# STM32U385 register map
File version: 1.0
CPU: CM33 r0p1, little endian, MPU, FPU, 4 interrupt priority bits
Registers are 32-bit, read-write, reset 0x0 unless marked. A register's access mark holds for its fields unless they carry their own. Offsets are from the block's base; [hi:lo] are bit positions; {n}, {i} and the like mark numbered series.

## GTZC1_MPCBB1 — GTZC1_MPCBB1 Address block
Base 0x40032C00
Same registers: SEC_GTZC1_MPCBB1 0x50032C00
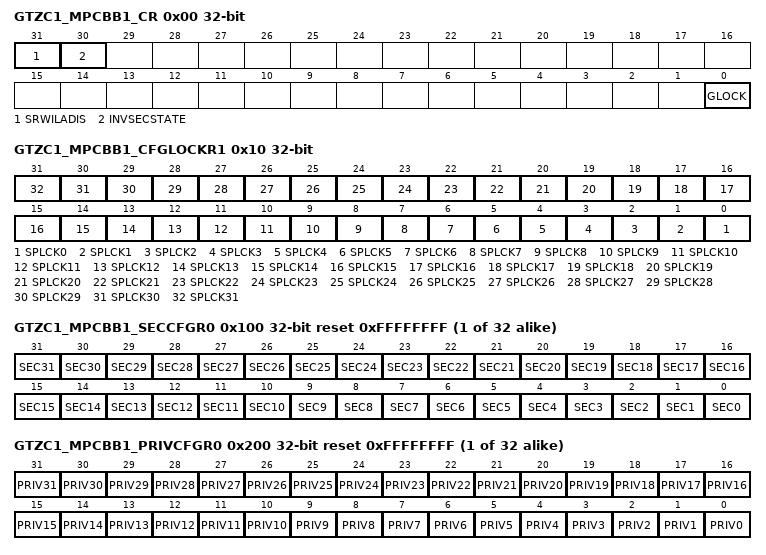
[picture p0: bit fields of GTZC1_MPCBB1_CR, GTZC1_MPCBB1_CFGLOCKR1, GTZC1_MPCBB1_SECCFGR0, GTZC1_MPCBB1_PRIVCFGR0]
0x00 GTZC1_MPCBB1_CR — GTZC1 SRAM1 MPCBB control register
  [31] SRWILADIS — This bit disables the detection of an illegal access when a secure read/write transaction access a non-secure blocks of the block-based SRAM (secure fetch on non-secure block is always considered illegal). 0: enabled, secure read/write access not allowed on non-secure SRAM block 1: disabled, secure read/write access allowed on non-secure SRAM block
    0=enabled, secure read/write access not allowed on non-secure SRAM block; 1=disabled, secure read/write access allowed on non-secure SRAM block
  [30] INVSECSTATE — This bit is used to define the internal SRAMs clocks control in RCC as secure or not. 0: SRAMs clocks are secure if a secure area exists in the MPCBB. It is non secure if there is no secure area. 1: SRAMs clocks are non-secure even if a secure area exists in the MPCBB, and secure even if no secure block is set in the MPCBB.
    0=SRAMs clocks are secure if a secure area exists in the MPCBB. It is non secure if there is no secure area.; 1=SRAMs clocks are non-secure even if a secure area exists in the MPCBB, and secure even if no secure block is set in the MPCBB
  [0] GLOCK — This bit is cleared by default and once set, it can not be reset until system reset. 0: control register not locked 1: control register locked
    0=control register not locked; 1=control register locked
0x10 GTZC1_MPCBB1_CFGLOCKR1 — GTZC1 SRAM1 MPCBB configuration lock register 1
  [n] SPLCK{n} (n=0..31) — This bit is set by software and can be cleared only by system reset. 0: GTZC1_MPCBB1_SECCFGR{n} and GTZC1_MPCBB1_PRIVCFGR{n} can be written. 1: Writes to GTZC1_MPCBB1_SECCFGR{n} and GTZC1_MPCBB1_PRIVCFGR{n} are ignored
    0=GTZC1_MPCBB1_SECCFGR{n} and GTZC1_MPCBB1_PRIVCFGR{n} can be written; 1=Writes to GTZC1_MPCBB1_SECCFGR{n} and GTZC1_MPCBB1_PRIVCFGR{n} are ignored
{0x100+4i} GTZC1_MPCBB1_SECCFGR{i} reset 0xFFFFFFFF (i=0..31) — GTZC1 SRAM1 MPCBB security configuration for super-block {i} register
  [n] SEC{n} (n=0..31) — Unprivileged write to this bit is ignored if PRIV{n} bit is set in GTZC1_MPCBB1_PRIVCFGR{i}. Writes are ignored if SPLCK{i} bit is set in GTZC1_MPCBB1_CFGLOCKR1. 0: Non-secure access only to block {n}, belonging to super-block {i}. Secure access is also allowed if the SRWILADIS bit is set in GTZC1_MPCBBz_CR. 1: Secure access only to block {n}, belonging to super-block {i}.
    0=Non-secure access only to block {n}, belonging to super-block {i}. Secure access is also allowed if the SRWILADIS bit is set in GTZC1_MPCBBz_CR.; 1=Secure access only to block {n}, belonging to super-block {i}
{0x200+4i} GTZC1_MPCBB1_PRIVCFGR{i} reset 0xFFFFFFFF (i=0..31) — GTZC1 SRAM1 MPCBB privileged configuration for super-block {i} register
  [n] PRIV{n} (n=0..31) — Non-secure write to this bit is ignored if SEC{n} bit is set in GTZC1_MPCBB1_SECCFGR{i}. Writes are ignored if SPLCK{i} bit is set in GTZC1_MPCBB1_CFGLOCKR1. 0: Privileged and unprivileged access to block {n}, belonging to super-block {i} 1: Only privileged access to block {n}, belonging to super-block {i}
    0=Privileged and unprivileged access to block {n}, belonging to super-block {i}; 1=Only privileged access to block {n}, belonging to super-block {i}

## GTZC1_MPCBB2 — GTZC1_MPCBB2 Address block
Base 0x40033000
Same registers: SEC_GTZC1_MPCBB2 0x50033000
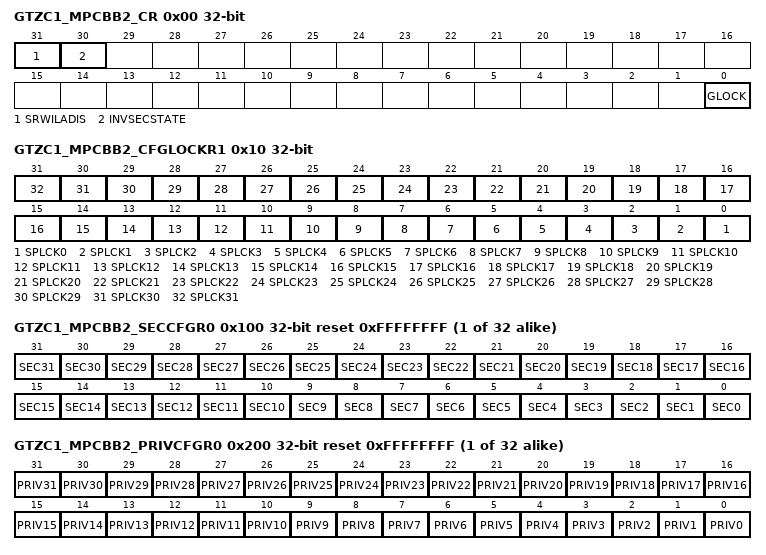
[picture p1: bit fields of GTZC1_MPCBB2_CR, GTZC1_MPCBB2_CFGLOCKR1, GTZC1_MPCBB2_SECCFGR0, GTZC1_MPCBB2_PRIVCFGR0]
0x00 GTZC1_MPCBB2_CR — GTZC1 SRAM2 MPCBB control register
  [31] SRWILADIS — This bit disables the detection of an illegal access when a secure read/write transaction access a non-secure blocks of the block-based SRAM (secure fetch on non-secure block is always considered illegal). 0: enabled, secure read/write access not allowed on non-secure SRAM block 1: disabled, secure read/write access allowed on non-secure SRAM block
    0=enabled, secure read/write access not allowed on non-secure SRAM block; 1=disabled, secure read/write access allowed on non-secure SRAM block
  [30] INVSECSTATE — This bit is used to define the internal SRAMs clocks control in RCC as secure or not. 0: SRAMs clocks are secure if a secure area exists in the MPCBB. It is non secure if there is no secure area. 1: SRAMs clocks are non-secure even if a secure area exists in the MPCBB, and secure even if no secure block is set in the MPCBB.
    0=SRAMs clocks are secure if a secure area exists in the MPCBB. It is non secure if there is no secure area.; 1=SRAMs clocks are non-secure even if a secure area exists in the MPCBB, and secure even if no secure block is set in the MPCBB
  [0] GLOCK — This bit is cleared by default and once set, it can not be reset until system reset. 0: control register not locked 1: control register locked
    0=control register not locked; 1=control register locked
0x10 GTZC1_MPCBB2_CFGLOCKR1 — GTZC1 SRAM2 MPCBB configuration lock register 1
  [n] SPLCK{n} (n=0..31) — This bit is set by software and can be cleared only by system reset. 0: GTZC1_MPCBB2_SECCFGR{n} and GTZC1_MPCBB2_PRIVCFGR{n} can be written. 1: Writes to GTZC1_MPCBB2_SECCFGR{n} and GTZC1_MPCBB2_PRIVCFGR{n} are ignored
    0=GTZC1_MPCBB2_SECCFGR{n} and GTZC1_MPCBB2_PRIVCFGR{n} can be written; 1=Writes to GTZC1_MPCBB2_SECCFGR{n} and GTZC1_MPCBB2_PRIVCFGR{n} are ignored
{0x100+4i} GTZC1_MPCBB2_SECCFGR{i} reset 0xFFFFFFFF (i=0..31) — GTZC1 SRAM2 MPCBB security configuration for super-block {i} register
  [n] SEC{n} (n=0..31) — Unprivileged write to this bit is ignored if PRIV{n} bit is set in GTZC1_MPCBB2_PRIVCFGR{i}. Writes are ignored if SPLCK{i} bit is set in GTZC1_MPCBB2_CFGLOCKR1. 0: Non-secure access only to block {n}, belonging to super-block {i}. Secure access is also allowed if the SRWILADIS bit is set in GTZC1_MPCBBz_CR. 1: Secure access only to block {n}, belonging to super-block {i}.
    0=Non-secure access only to block {n}, belonging to super-block {i}. Secure access is also allowed if the SRWILADIS bit is set in GTZC1_MPCBBz_CR.; 1=Secure access only to block {n}, belonging to super-block {i}
{0x200+4i} GTZC1_MPCBB2_PRIVCFGR{i} reset 0xFFFFFFFF (i=0..31) — GTZC1 SRAM2 MPCBB privileged configuration for super-block {i} register
  [n] PRIV{n} (n=0..31) — Non-secure write to this bit is ignored if SEC{n} bit is set in GTZC1_MPCBB2_SECCFGR{i}. Writes are ignored if SPLCK{i} bit is set in GTZC1_MPCBB2_CFGLOCKR1. 0: Privileged and unprivileged access to block {n}, belonging to super-block {i} 1: Only privileged access to block {n}, belonging to super-block {i}
    0=Privileged and unprivileged access to block {n}, belonging to super-block {i}; 1=Only privileged access to block {n}, belonging to super-block {i}

## Notices in the file
Copyright (c) 2025 STMicroelectronics.
SPDx-License-Identifier: Apache-2.0
Licensed under the Apache License, Version 2.0 (the "License");
you may not use this file except in compliance with the License.
You may obtain a copy of the License at
http://www.apache.org/licenses/LICENSE-2.0
Unless required by applicable law or agreed to in writing, software
distributed under the License is distributed on an "AS IS" BASIS,
WITHOUT WARRANTIES OR CONDITIONS OF ANY KIND, either express or implied.
See the License for the specific language governing permissions and
limitations under the License.
